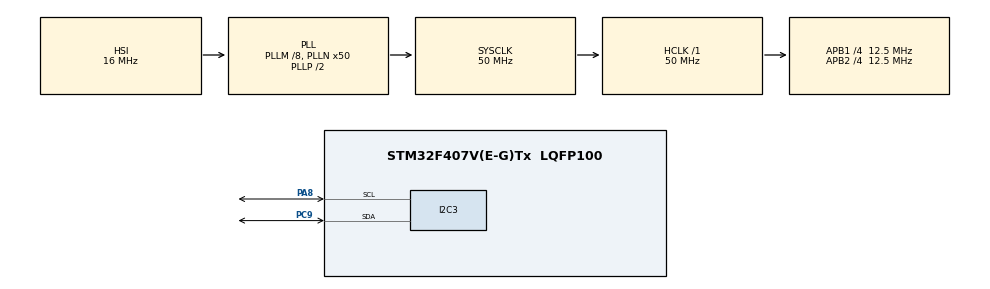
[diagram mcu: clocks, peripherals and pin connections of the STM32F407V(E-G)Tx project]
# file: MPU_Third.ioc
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Mcu.Family=STM32F4
Mcu.Name=STM32F407V(E-G)Tx
Mcu.Package=LQFP100
NVIC.PriorityGroup=NVIC_PRIORITYGROUP_0
PA8.Mode=I2C
PA8.Signal=I2C3_SCL
PC9.Mode=I2C
PC9.Signal=I2C3_SDA
ProjectManager.HeapSize=0x200
ProjectManager.StackSize=0x400
ProjectManager.TargetToolchain=STM32CubeIDE
RCC.48MHZClocksFreq_Value=14285714.285714285
RCC.AHBFreq_Value=50000000
RCC.APB1CLKDivider=RCC_HCLK_DIV4
RCC.APB1Freq_Value=12500000
RCC.APB1TimFreq_Value=25000000
RCC.APB2CLKDivider=RCC_HCLK_DIV4
RCC.APB2Freq_Value=12500000
RCC.APB2TimFreq_Value=25000000
RCC.CortexFreq_Value=50000000
RCC.HCLKFreq_Value=50000000
RCC.HSE_VALUE=8000000
RCC.HSI_VALUE=16000000
RCC.PLLM=8
RCC.PLLN=50
RCC.PLLQ=7
RCC.SYSCLKFreq_VALUE=50000000
RCC.SYSCLKSource=RCC_SYSCLKSOURCE_PLLCLK
RCC.VCOOutputFreq_Value=100000000
board=STM32F407G-DISC1

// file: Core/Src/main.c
/* USER CODE BEGIN Header */
/**
  ******************************************************************************
  * @file           : main.c
  * @brief          : Main program body
  ******************************************************************************
  * @attention
  *
  * Copyright (c) 2023 STMicroelectronics.
  * All rights reserved.
  *
  * This software is licensed under terms that can be found in the LICENSE file
  * in the root directory of this software component.
  * If no LICENSE file comes with this software, it is provided AS-IS.
  *
  ******************************************************************************
  */
/* USER CODE END Header */
#include "main.h"

/* USER CODE BEGIN Includes */
#include <stdio.h>
#include <string.h>
#include <stdlib.h>
#include <math.h>
#include <stdbool.h>
/* USER CODE END Includes */

/* USER CODE BEGIN PD */
#define MPU6050_ADDR 0x68<<1  //
#define SMPLRT_DIV_REG 0x19		//
#define GYRO_CNFG_REG 0x1B		//
#define ACC_CNFG_REG 0x1C		//
// #define ACCEL_XOUT_H_REG 0x3B //
// #define TEMP_OUT_H_REG 0x41	//
// #define GYRO_XOUT_H_REG 0x43	//
#define PWR_MGMT_1_REG 0x6B
#define WHO_AM_I_REG 0x75
#define LPF_REG 0x1A			//
/* USER CODE END PD */

I2C_HandleTypeDef hi2c3;

/* USER CODE BEGIN PV */
uint8_t Data;
uint8_t tuffer[6],cuffer[6];
int16_t gyro_raw[3],acc_raw[3];
float angle_pitch_gyro, angle_roll_gyro;
float gyro_cal[3],acc_cal[3];
int16_t acc_total_vector;
float angle_pitch_acc, angle_roll_acc, angle_pitch_acc_sum, angle_roll_acc_sum,acc_total_vector_sum;
float angle_pitch,angle_roll;
HAL_StatusTypeDef set_gyro;
float i;
float prevtime,prevtime1,time1,elapsedtime1,prevtime2,time2,elapsedtime2;
/* USER CODE END PV */

void SystemClock_Config(void);
static void MX_GPIO_Init(void);
static void MX_I2C3_Init(void);

/* USER CODE BEGIN 0 */

void MPU6050_Init(void)
{

		// power management register 0X6B we should write all 0's to wake the sensor up
		Data = 0x00;
		HAL_I2C_Mem_Write(&hi2c3, MPU6050_ADDR, PWR_MGMT_1_REG, 1,&Data, 1, HAL_MAX_DELAY);

	/*	// Set DATA RATE of 1KHz by writing SMPLRT_DIV register
		Data = 0x07;
		HAL_I2C_Mem_Write(&hi2c3, MPU6050_ADDR, SMPLRT_DIV_REG, 1, &Data, 1, HAL_MAX_DELAY);
	*/
		Data = 0x10;
		HAL_I2C_Mem_Write (&hi2c3, MPU6050_ADDR, ACC_CNFG_REG, 1, &Data, 1, HAL_MAX_DELAY);

		Data = 0x08;
		HAL_I2C_Mem_Write (&hi2c3, MPU6050_ADDR, GYRO_CNFG_REG, 1, &Data, 1, HAL_MAX_DELAY);

		for(i=0; i<2000; i++)
		      {
		    	  prevtime2 = time2;
		    	  time2 = HAL_GetTick();
		    	  elapsedtime2=(time2-prevtime2)*1000;

		    	  cuffer[0]=0x43;
		    	  HAL_I2C_Master_Transmit(&hi2c3,MPU6050_ADDR,cuffer,1,HAL_MAX_DELAY);
		    	  HAL_I2C_Master_Receive(&hi2c3,MPU6050_ADDR,cuffer,6,HAL_MAX_DELAY);

		    	  gyro_raw[0] = (cuffer[0] << 8 | cuffer[1]);
		    	  gyro_raw[1] = (cuffer[2] << 8 | cuffer[3]);
		    	  gyro_raw[2] = (cuffer[4] << 8 | cuffer[5]);

		    	  gyro_cal[0] += gyro_raw[0];
		    	  gyro_cal[1] += gyro_raw[1];
		    	  gyro_cal[2] += gyro_raw[2];

		    	  HAL_Delay(3);

		      }

		      gyro_cal[0] /= 2000;
		      gyro_cal[1] /= 2000;
		      gyro_cal[2] /= 2000;

		      HAL_Delay(1000);

}
void MPU_6050_Read_Datas(void)
{
	prevtime1 = time1;
	time1 = HAL_GetTick();
	elapsedtime1=(time1-prevtime1)*1000;

	tuffer[0]=0x3B;
	HAL_I2C_Master_Transmit(&hi2c3,MPU6050_ADDR,tuffer,1,HAL_MAX_DELAY);
	HAL_I2C_Master_Receive(&hi2c3,MPU6050_ADDR,tuffer,6,HAL_MAX_DELAY);

	acc_raw[0] = (int16_t)(tuffer[0] << 8 | tuffer[1]);
	acc_raw[1] = (int16_t)(tuffer[2] << 8 | tuffer[3]);
	acc_raw[2] = (int16_t)(tuffer[4] << 8 | tuffer[5]);

	cuffer[0]=0x43;  // ACCEL_XOUT_H_REG
	HAL_I2C_Master_Transmit(&hi2c3,MPU6050_ADDR,cuffer,1, HAL_MAX_DELAY);
	HAL_I2C_Master_Receive (&hi2c3, MPU6050_ADDR, cuffer, 6, HAL_MAX_DELAY);

	gyro_raw[0] = (cuffer[0] << 8 | cuffer[1]);
	gyro_raw[1] = (cuffer[2] << 8 | cuffer[3]);
	gyro_raw[2] = (cuffer[4] << 8 | cuffer[5]);

	gyro_raw[0] -= gyro_cal[0];
	gyro_raw[1] -= gyro_cal[1];
	gyro_raw[2] -= gyro_cal[2];

	angle_pitch_gyro += gyro_raw[0] * 0.0000611;
	angle_roll_gyro += gyro_raw[1] * 0.0000611;

	angle_pitch_gyro += angle_roll_gyro * sin(gyro_raw[2] * 0.000001066);
	angle_roll_gyro -= angle_pitch_gyro * sin(gyro_raw[2] * 0.000001066);

	acc_total_vector = sqrt((acc_raw[0]*acc_raw[0])+(acc_raw[1]*acc_raw[1])+(acc_raw[2]*acc_raw[2]));

	angle_pitch_acc = asin((float)acc_raw[1]/acc_total_vector)* 57.296;
	angle_roll_acc = asin((float)acc_raw[0]/acc_total_vector)* -57.296;

	angle_pitch_acc -= 0;//0.05;
	angle_roll_acc -= 0;//-1.32;

	if(set_gyro)
	{
	 angle_pitch = angle_pitch_gyro * 0.9996 + angle_pitch_acc * 0.0004;
	 angle_roll = angle_roll_gyro * 0.9996 + angle_roll_acc * 0.0004;
	}
	else
    {
 	 angle_pitch = angle_pitch_acc;
 	 set_gyro = true;
	}

	while((HAL_GetTick() - prevtime)*1000 < 4000);
	prevtime = HAL_GetTick();
}

/* USER CODE END 0 */

int main(void)
{

  /* MCU Configuration--------------------------------------------------------*/

  /* Reset of all peripherals, Initializes the Flash interface and the Systick. */
  HAL_Init();

  /* Configure the system clock */
  SystemClock_Config();

  /* Initialize all configured peripherals */
  MX_GPIO_Init();
  MX_I2C3_Init();
  MPU6050_Init();
  /* Infinite loop */
  while (1)
  {

    /* USER CODE BEGIN 3 */
	  MPU_6050_Read_Datas();
  }
  /* USER CODE END 3 */
}

void SystemClock_Config(void)
{
  RCC_OscInitTypeDef RCC_OscInitStruct = {0};
  RCC_ClkInitTypeDef RCC_ClkInitStruct = {0};

  /** Configure the main internal regulator output voltage
  */
  __HAL_RCC_PWR_CLK_ENABLE();
  __HAL_PWR_VOLTAGESCALING_CONFIG(PWR_REGULATOR_VOLTAGE_SCALE1);

  /** Initializes the RCC Oscillators according to the specified parameters
  * in the RCC_OscInitTypeDef structure.
  */
  RCC_OscInitStruct.OscillatorType = RCC_OSCILLATORTYPE_HSI;
  RCC_OscInitStruct.HSIState = RCC_HSI_ON;
  RCC_OscInitStruct.HSICalibrationValue = RCC_HSICALIBRATION_DEFAULT;
  RCC_OscInitStruct.PLL.PLLState = RCC_PLL_ON;
  RCC_OscInitStruct.PLL.PLLSource = RCC_PLLSOURCE_HSI;
  RCC_OscInitStruct.PLL.PLLM = 8;
  RCC_OscInitStruct.PLL.PLLN = 50;
  RCC_OscInitStruct.PLL.PLLP = RCC_PLLP_DIV2;
  RCC_OscInitStruct.PLL.PLLQ = 7;
  if (HAL_RCC_OscConfig(&RCC_OscInitStruct) != HAL_OK)
  {
    Error_Handler();
  }

  /** Initializes the CPU, AHB and APB buses clocks
  */
  RCC_ClkInitStruct.ClockType = RCC_CLOCKTYPE_HCLK|RCC_CLOCKTYPE_SYSCLK
                              |RCC_CLOCKTYPE_PCLK1|RCC_CLOCKTYPE_PCLK2;
  RCC_ClkInitStruct.SYSCLKSource = RCC_SYSCLKSOURCE_PLLCLK;
  RCC_ClkInitStruct.AHBCLKDivider = RCC_SYSCLK_DIV1;
  RCC_ClkInitStruct.APB1CLKDivider = RCC_HCLK_DIV4;
  RCC_ClkInitStruct.APB2CLKDivider = RCC_HCLK_DIV4;

  if (HAL_RCC_ClockConfig(&RCC_ClkInitStruct, FLASH_LATENCY_1) != HAL_OK)
  {
    Error_Handler();
  }
}

static void MX_I2C3_Init(void)
{

  hi2c3.Instance = I2C3;
  hi2c3.Init.ClockSpeed = 100000;
  hi2c3.Init.DutyCycle = I2C_DUTYCYCLE_2;
  hi2c3.Init.OwnAddress1 = 0;
  hi2c3.Init.AddressingMode = I2C_ADDRESSINGMODE_7BIT;
  hi2c3.Init.DualAddressMode = I2C_DUALADDRESS_DISABLE;
  hi2c3.Init.OwnAddress2 = 0;
  hi2c3.Init.GeneralCallMode = I2C_GENERALCALL_DISABLE;
  hi2c3.Init.NoStretchMode = I2C_NOSTRETCH_DISABLE;
  if (HAL_I2C_Init(&hi2c3) != HAL_OK)
  {
    Error_Handler();
  }

}

static void MX_GPIO_Init(void)
{

  /* GPIO Ports Clock Enable */
  __HAL_RCC_GPIOC_CLK_ENABLE();
  __HAL_RCC_GPIOA_CLK_ENABLE();

}

void Error_Handler(void)
{
  __disable_irq();
  while (1)
  {
  }
}
